# A31L21x register map
Vendor: VENDOR ABOV Semiconductor Co., Ltd.; Series: A31L21x; File version: 1.0
CPU: CM0+ r0p1, little endian, no MPU, no FPU, VTOR, 2 interrupt priority bits
Registers are 32-bit, read-write, reset 0x0 unless marked. A register's access mark holds for its fields unless they carry their own. Offsets are from the block's base; [hi:lo] are bit positions; {n}, {i} and the like mark numbered series; 'fields as' and 'values as' point back to an identical list.

## AES — AES128
Base 0x40005E00
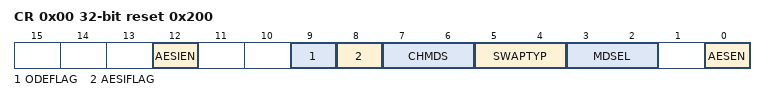
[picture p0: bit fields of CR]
0x00 CR reset 0x200 — AES Control Register
  [12] AESIEN — AES-128 Computation Finish Interrupt Enable
    0=Disable AES-128 interrupt; 1=Enable AES-128 interrupt
  [9] ODEFLAG ro — Output Data Empty flag
    0=Available (There is output data to read.); 1=Empty (There is no output data to read. That is, the output data register is empty.)
  [8] AESIFLAG — AES-128 Computation Finish Interrupt flag
    0=No request occurred; 1=Request occurred. This bit is cleared to '0' when write '1'.
  [7:6] CHMDS — Chaining Mode Selection
    0=ECB (Electronic code book (ECB)); 1=CBC (Cipher block chaining (CBC)); 2=CTR (Counter mode (CTR))
  [5:4] SWAPTYP — Input/Output Data Swap Type Selection
    0=None (No swap); 1=Half word swap; 2=Byte swap; 3=Bit (Bit swap)
  [3:2] MDSEL — AES-128 Operation Mode Selection
    0=Encryption (Select cipher (Encryption) mode); 1=Decryption (Select inverse cipher (Decryption) mode); 2=KeyExpansion (Select key expansion function)
  [0] AESEN — AES-128 Operation Enable
    0=Disable AES-128; 1=Enable AES-128 (The AES block will be initialized for a new block processing)
0x08 INDR wo reset not defined — AES Input Data Register
0x0C OUTDR ro reset not defined — AES Output Data Register
{0xC+4i} KEYDR{i} reset not defined (i=1..4) — AES Key Data Register {i}
{0x1C+4i} IVDR{i} reset not defined (i=1..4) — AES Initial Vector Data Register {i}
{0x2C+4i} INRDR{i} ro reset not defined (i=1..4) — AES Input Read Data Register {i}
{0x3C+4i} KEYOUTDR{i} ro reset not defined (i=1..4) — AES Key Output Data Register {i}

## RNG — Random Number Generator
Base 0x40005F00
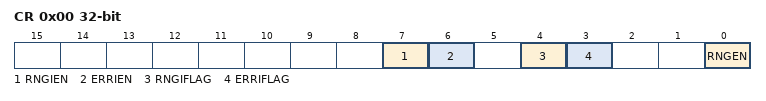
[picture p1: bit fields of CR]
0x00 CR — Random Number Generator Control Register
  [7] RNGIEN — Random Data Ready Interrupt Enable
    0=Disable random number generator interrupt; 1=Enable random number generator interrupt
  [6] ERRIEN ro — Error Detection Interrupt Enable
    0=Disable error detection interrupt; 1=Enable error detection interrupt
  [4] RNGIFLAG — Random Data Ready Interrupt flag
    0=No request occurred; 1=Request occurred. This bit is cleared to '0' when write '1'.
  [3] ERRIFLAG — Error Detection Interrupt flag
    values as RNGIFLAG
  [0] RNGEN — Random Number Generator Enable
    0=Disable random number generator; 1=Enable random number generator. (Clear 3-bits counter and start)
0x04 OUTDR ro reset not defined — Random Number Generator Output Data Register

## DMACn — DMA Controller Channel n
Base 0x51000000
Same registers: DMAC0 0x40005D00, DMAC1 0x40005D20, DMAC2 0x40005D40, DMAC3 0x40005D60, DMAC4 0x40005D80, DMAC5 0x40005DA0, DMAC6 0x40005DC0
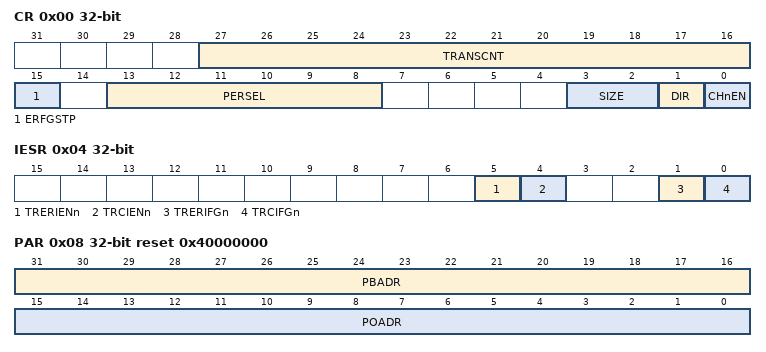
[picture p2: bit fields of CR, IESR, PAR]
0x00 CR — DMA Channel n Control Register
  [27:16] TRANSCNT — The number of times to transfer
  [15] ERFGSTP — Error Flag Stop
    0=Disable DMA stop function by an error of peripheral; 1=Enable DMA stop function by an error of peripheral
  [13:8] PERSEL — Peripheral Selection
    0=Idle (Channel idle); 1=ADC (ADC Output); 2=SPI0Rx; 3=SPI0Tx; 4=SPI1Rx; 5=SPI1Tx; 6=USART10Rx; 7=USART10Tx; 8=I2C0Rx; 9=I2C0Tx; 10=I2C1Rx; 11=I2C1Tx; 12=UART0Rx; 13=UART0Tx; 16=LPUART0Rx; 17=LPUART0Tx; 18=SC0Rx; 19=SC0Tx; 22=SPI2Rx; 23=SPI2Tx; 24=SPI3Rx; 25=SPI3Tx; 26=USART11Rx; 27=USART11Tx; 28=I2C2Rx; 29=I2C2Tx; 30=AESOutData (Output Data of AES 128-bit); 31=AESInData (Input Data of AES 128-bit); 32=LPUART1Rx; 33=LPUART1Tx
  [3:2] SIZE — Transfer Size Selection
    0=8 bits; 1=16 bits; 2=32 bits
  [1] DIR — Transfer Direction
    0=MemToPeri (Transfer is from memory to peripheral.); 1=PeriToMem (Transfer is from peripheral to memory.)
  [0] CHnEN — DMA Channel Enable
    0=Disable channel n; 1=Enable channel n
0x04 IESR — DMA Channel n Interrupt Enable and Status Register
  [5] TRERIENn — Transfer Error Interrupt Enable
    0=Disable transfer error interrupt; 1=Enable transfer error interrupt
  [4] TRCIENn — Transfer Complete Interrupt Enable
    0=Disable transfer complete interrupt; 1=Enable transfer complete interrupt
  [1] TRERIFGn — Transfer Error Interrupt Flag
    0=No request occurred; 1=Request occurred
  [0] TRCIFGn — Transfer Complete Interrupt Flag
    0=No request occurred; 1=Request occurred
0x08 PAR reset 0x40000000 — DMA Channel n Peripheral Address Register
  [31:16] PBADR — Peripheral Base Address
  [15:0] POADR — Peripheral Offset Address
0x0C MAR reset 0x20000000 — DMA Channel n Memory Address Register
  [31:0] MAR — Memory Address
